# CY8C5868AXI_LP035 register map
File version: 0.1
Registers are 8-bit, read-write, no defined reset value unless marked. A register's access mark holds for its fields unless they carry their own. Offsets are from the block's base; [hi:lo] are bit positions; 'fields as' and 'values as' point back to an identical list.

## StatusReg_iButton5thCRCBit
Base 0x40006462
0x00 StatusReg_iButton5thCRCBit_STATUS_REG
0x20 StatusReg_iButton5thCRCBit_MASK_REG
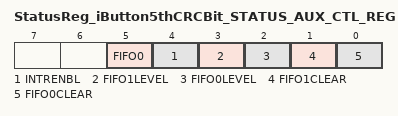
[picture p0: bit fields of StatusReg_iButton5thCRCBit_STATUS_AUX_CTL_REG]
0x30 StatusReg_iButton5thCRCBit_STATUS_AUX_CTL_REG
  [5] FIFO0 — FIFO0 clear
    1=ENABLED (Enable counter); 0=DISABLED (Disable counter)
  [4] INTRENBL — Enables or disables the Interrupt
    1=ENABLED (Interrupt enabled); 0=DISABLED (Interrupt disabled)
  [3] FIFO1LEVEL — FIFO level
    1=ENABLED (FIFO LVL: input mode: FIFO at least 1/2 empty; output mode: FIFO at least 1/2 full); 0=DISABLED (FIFO LVL: input mode: FIFO not full; output mode: FIFO not empty)
  [2] FIFO0LEVEL — FIFO level
    values as FIFO1LEVEL
  [1] FIFO1CLEAR — FIFO clear
    1=ENABLED (Clear FIFO state); 0=DISABLED (Normal FIFO operation)
  [0] FIFO0CLEAR — FIFO clear
    values as FIFO1CLEAR

## CRC_Security
Base 0x40006406
0x00 SINGLE_CYCLE_SEED — Current seed value
0x20 SINGLE_CYCLE_POLYNOMIAL — Current polynomial value
0x40 SINGLE_CYCLE_DEFAULT — Default seed value

## Clock_iButton
Base 0x40006470
0x00 Clock_iButton_CONTROL_REG

## Input_iButton
Base 0x40006474
Registers as Clock_iButton (with Clock_iButton read as Input_iButton).

## Clock_CRC
Base 0x40006478
Registers as Clock_iButton (with Clock_iButton read as Clock_CRC).

## Reset_DispenserTimer
Base 0x40006575
Registers as Clock_iButton (with Clock_iButton read as Reset_DispenserTimer).

## Reset_CRC
Base 0x40006577
Registers as Clock_iButton (with Clock_iButton read as Reset_CRC).

## Reset_iButton
Base 0x40006473
Registers as Clock_iButton (with Clock_iButton read as Reset_iButton).

## RF_Physical — UART
Base 0x00000000
0x40006425 RX_RF_Physical_RX_ADDRESS1 — RX Address1 Register
0x40006435 RX_RF_Physical_RX_ADDRESS2 — RX Address2 Register
0x40006445 RX_RF_Physical_RX_DATA — RX Data Register
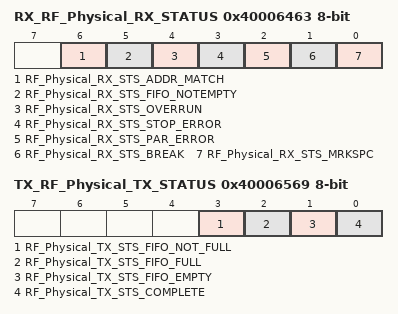
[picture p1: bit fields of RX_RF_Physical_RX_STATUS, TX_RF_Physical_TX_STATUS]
0x40006463 RX_RF_Physical_RX_STATUS — RX status register
  [6] RF_Physical_RX_STS_ADDR_MATCH ro, [5] RF_Physical_RX_STS_FIFO_NOTEMPTY ro, [4] RF_Physical_RX_STS_OVERRUN ro, [3] RF_Physical_RX_STS_STOP_ERROR ro, [2] RF_Physical_RX_STS_PAR_ERROR ro, [1] RF_Physical_RX_STS_BREAK ro, [0] RF_Physical_RX_STS_MRKSPC ro
0x40006548 TX_RF_Physical_TX_DATA — TX Data Register
0x40006569 TX_RF_Physical_TX_STATUS — TX status register
  [3] RF_Physical_TX_STS_FIFO_NOT_FULL ro, [2] RF_Physical_TX_STS_FIFO_FULL ro, [1] RF_Physical_TX_STS_FIFO_EMPTY ro, [0] RF_Physical_TX_STS_COMPLETE ro

## Timer_DispenserState
Base 0x00000000
0x40006504 Timer_DispenserState_COUNTER 16-bit — UDB.A0 - Current Down Counter Value
0x40006524 Timer_DispenserState_PERIOD 16-bit — UDB.D0 - Assigned Period
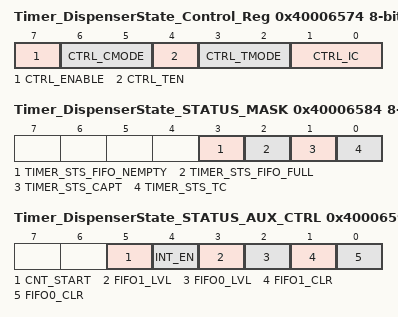
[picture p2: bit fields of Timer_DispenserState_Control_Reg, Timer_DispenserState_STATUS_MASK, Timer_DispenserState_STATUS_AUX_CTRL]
0x40006574 Timer_DispenserState_Control_Reg — UDB Control Register - Assigned Control Register Value
  [7] CTRL_ENABLE — Enable the Timer
  [6:5] CTRL_CMODE — Capture Mode
  [4] CTRL_TEN — Trigger Enable Bit
  [3:2] CTRL_TMODE — Trigger Mode
  [1:0] CTRL_IC — Interrupt Count
0x40006584 Timer_DispenserState_STATUS_MASK — UDB Status bits Interrupt Mask Enable Register
  [3] TIMER_STS_FIFO_NEMPTY ro — FIFO Empty status
  [2] TIMER_STS_FIFO_FULL ro — FIFO Full Status
  [1] TIMER_STS_CAPT ro — Enables the Interrupt on Capture
  [0] TIMER_STS_TC ro — Enables the Interrupt on TC
0x40006594 Timer_DispenserState_STATUS_AUX_CTRL — UDB Auxilliary Control Register
  [5] CNT_START — FIFO0 clear
    0=E_CNT_START0 (Disable counter); 1=E_CNT_START1 (Enable counter)
  [4] INT_EN
    0=E_INT_EN0 (Interrupt disabled); 1=E_INT_EN1 (Interrupt enabled)
  [3] FIFO1_LVL — FIFO level
    0=E_FIFO_LVL_0 (FIFO LVL: input mode: FIFO not full; output mode: FIFO not empty); 1=E_FIFO_LVL_1 (FIFO LVL: input mode: FIFO at least 1/2 empty; output mode: FIFO at least 1/2 full)
  [2] FIFO0_LVL — FIFO level
    values as FIFO1_LVL
  [1] FIFO1_CLR — FIFO1 clear
    0=E_FIFO_CLR_0 (Normal FIFO operation); 1=E_FIFO_CLR_1 (Clear FIFO state)
  [0] FIFO0_CLR — FIFO0 clear
    values as FIFO1_CLR

## Dispenser — UART
Base 0x00000000
0x40006422 RX_Dispenser_RX_ADDRESS1 — RX Address1 Register
0x40006432 RX_Dispenser_RX_ADDRESS2 — RX Address2 Register
0x40006441 TX_Dispenser_TX_DATA — TX Data Register
0x40006442 RX_Dispenser_RX_DATA — RX Data Register
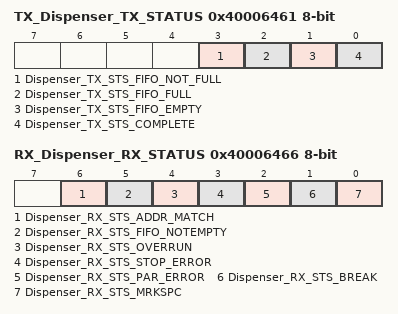
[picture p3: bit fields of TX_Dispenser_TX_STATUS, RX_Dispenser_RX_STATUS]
0x40006461 TX_Dispenser_TX_STATUS — TX status register
  [3] Dispenser_TX_STS_FIFO_NOT_FULL ro, [2] Dispenser_TX_STS_FIFO_FULL ro, [1] Dispenser_TX_STS_FIFO_EMPTY ro, [0] Dispenser_TX_STS_COMPLETE ro
0x40006466 RX_Dispenser_RX_STATUS — RX status register
  [6] Dispenser_RX_STS_ADDR_MATCH ro, [5] Dispenser_RX_STS_FIFO_NOTEMPTY ro, [4] Dispenser_RX_STS_OVERRUN ro, [3] Dispenser_RX_STS_STOP_ERROR ro, [2] Dispenser_RX_STS_PAR_ERROR ro, [1] Dispenser_RX_STS_BREAK ro, [0] Dispenser_RX_STS_MRKSPC ro

## Printer — UART
Base 0x00000000
0x40006428 RX_Printer_RX_ADDRESS1 — RX Address1 Register
0x40006438 RX_Printer_RX_ADDRESS2 — RX Address2 Register
0x40006448 RX_Printer_RX_DATA — RX Data Register
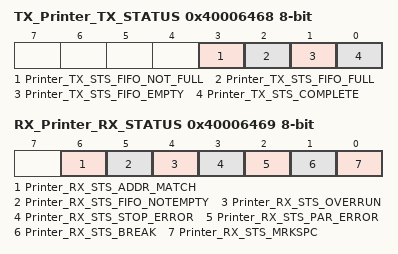
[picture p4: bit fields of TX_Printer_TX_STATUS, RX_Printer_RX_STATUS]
0x40006468 TX_Printer_TX_STATUS — TX status register
  [3] Printer_TX_STS_FIFO_NOT_FULL ro, [2] Printer_TX_STS_FIFO_FULL ro, [1] Printer_TX_STS_FIFO_EMPTY ro, [0] Printer_TX_STS_COMPLETE ro
0x40006469 RX_Printer_RX_STATUS — RX status register
  [6] Printer_RX_STS_ADDR_MATCH ro, [5] Printer_RX_STS_FIFO_NOTEMPTY ro, [4] Printer_RX_STS_OVERRUN ro, [3] Printer_RX_STS_STOP_ERROR ro, [2] Printer_RX_STS_PAR_ERROR ro, [1] Printer_RX_STS_BREAK ro, [0] Printer_RX_STS_MRKSPC ro
0x4000654B TX_Printer_TX_DATA — TX Data Register
